# MU3E_HISTOGRAM_STATISTICS register map
Vendor: Mu3e; Series: MU3E_FPGA_IP; File version: 26.3.0.0515
CMSIS-SVD description of the histogram statistics CSR window. BaseAddress is 0 because this file describes the relative CSR aperture of the IP; system integration supplies the live slave base address.
Registers are 32-bit, read-only, reset 0x0 unless marked. A register's access mark holds for its fields unless they carry their own. Offsets are from the block's base; lines under a group give offsets from that group; [hi:lo] are bit positions; {n}, {i} and the like mark numbered series; 'fields as' and 'values as' point back to an identical list; <NAME> marks a mode.

## Memory map
0x00000000 HISTOGRAM_STATISTICS_CSR size 0x4C — Relative 19-word CSR aperture for histogram statistics. The separate hist_bin data window is intentionally excluded because it is histogram memory, not control/status registers.

## HISTOGRAM_STATISTICS_CSR — Relative 19-word CSR aperture for histogram statistics. The separate hist_bin data window is intentionally excluded because it is histogram memory, not control/status registers.
Base 0x00000000
0x00 UID reset 0x48495354 — Software-visible IP identifier. Default ASCII "HIST" (0x48495354).
  [31:0] value — Compile-time or integration-time UID word. Default ASCII "HIST".
0x04 META rw — Read-multiplexed metadata word. Write meta_sel[1:0] before reading back: 0=VERSION, 1=DATE, 2=GIT, 3=INSTANCE_ID.
  [1:0] meta_sel — Selects the META read page.
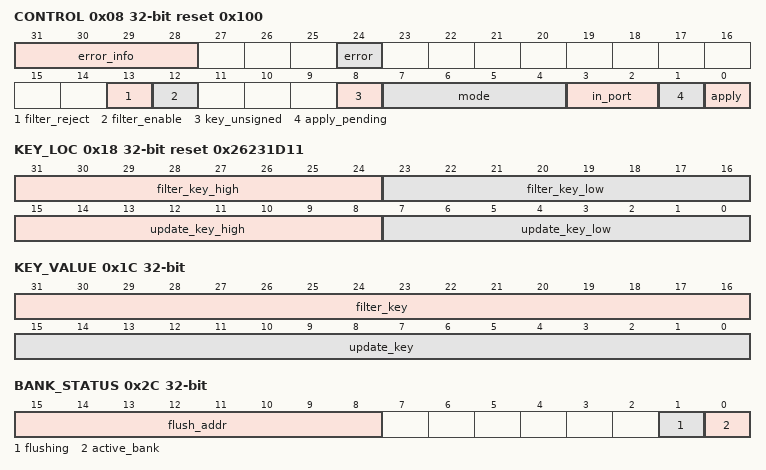
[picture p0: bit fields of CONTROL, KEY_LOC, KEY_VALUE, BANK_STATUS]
0x08 CONTROL rw reset 0x100 — Configuration apply, mode, key interpretation, filter control, and validation status.
  [31:28] error_info ro — Validation error code. 0x1 indicates invalid bounds in auto-right-bound mode; 0x2 indicates invalid in_port.
  [24] error ro — Set when the last apply request failed CSR validation.
  [13] filter_reject — 0 accepts matching events, 1 rejects matching events.
  [12] filter_enable — Enables the runtime filter-key comparison.
  [8] key_unsigned — 1 selects unsigned update-key interpretation, 0 selects signed extraction.
  [7:4] mode — Mode selector. Mode 0 bins the selected stream key directly. Mode 1 bins stream delay: for in_port 1 or 2, data[86:39] from the selected extended source is the true hit timestamp; for in_port 0, the selected update-key slice is used as before. Negative signed values -1..-6 route debug_1..debug_6 individually; -7 samples signed MTS-delay streams on debug_1 and debug_2 together. In debug modes the CSR filter compares a synthetic debug word: bits [15:0] sample, [23:16] zero-based debug source, [31:24] absolute debug mode.
  [3:2] in_port — Histogram ingress source. 0 selects the normal fill-in merge, 1 selects hit_type1_extended_0, and 2 selects hit_type1_extended_1. Value 3 is rejected on apply.
  [1] apply_pending ro — 1 while a committed configuration is waiting to settle into the live datapath.
  [0] apply — Write 1 to request that the staged configuration becomes active after the ingress path drains.
0x0C LEFT_BOUND rw — Signed left boundary of the histogram range.
  [31:0] value — Signed left boundary.
0x10 RIGHT_BOUND rw — Signed right boundary of the histogram range. Recomputed at apply time when BIN_WIDTH != 0.
  [31:0] value — Signed right boundary.
0x14 BIN_WIDTH rw — Bin width in key-space units. Set to 0 to keep explicit left and right bounds.
  [15:0] value — Bin width in key-space units.
0x18 KEY_LOC rw reset 0x26231D11 — Packed bit-slice locations for update-key and filter-key extraction.
  [31:24] filter_key_high — MSB of the filter-key slice inside the snooped data word. In debug modes this selects the synthetic debug word.
  [23:16] filter_key_low — LSB of the filter-key slice inside the snooped data word. In debug modes this selects the synthetic debug word.
  [15:8] update_key_high — MSB of the update-key slice inside the snooped data word.
  [7:0] update_key_low — LSB of the update-key slice inside the snooped data word.
0x1C KEY_VALUE rw — Packed runtime key overrides used by mode-dependent histogram logic.
  [31:16] filter_key — Literal filter-key comparison value.
  [15:0] update_key — Literal update-key override.
0x20 UNDERFLOW_COUNT — Count of keys mapped below the configured range.
  [31:0] value — Underflow event count.
0x24 OVERFLOW_COUNT — Count of keys mapped above the configured range.
  [31:0] value — Overflow event count.
0x28 INTERVAL_CFG rw — Ping-pong interval timer configuration in clock cycles.
  [31:0] value — Interval length in clock cycles.
0x2C BANK_STATUS — Ping-pong bank-selection and flush-progress status.
  [15:8] flush_addr — Bin index currently being cleared.
  [1] flushing — 1 while the next active bank is being cleared.
  [0] active_bank — Currently active write bank.
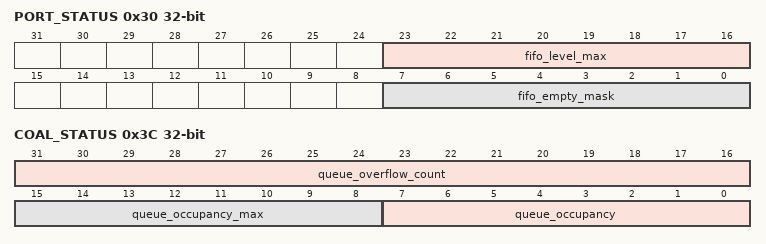
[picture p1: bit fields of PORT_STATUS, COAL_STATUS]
0x30 PORT_STATUS — Ingress FIFO empty-mask and maximum observed fill level.
  [23:16] fifo_level_max — Maximum observed FIFO fill level across the ingress-port pairs.
  [7:0] fifo_empty_mask — One bit per ingress FIFO. 1 indicates the corresponding FIFO is empty.
0x34 TOTAL_HITS — Live accepted-hit count in the current interval. Resets at manual clear and at every interval pulse.
  [31:0] value — Current-interval accepted-hit count.
0x38 DROPPED_HITS — Live dropped-hit count caused by FIFO or queue overflow in the current interval. Resets at manual clear and at every interval pulse.
  [31:0] value — Current-interval dropped-hit count.
0x3C COAL_STATUS — Coalescing-queue occupancy, occupancy maximum, and overflow count.
  [31:16] queue_overflow_count — Total number of queue-overflow events.
  [15:8] queue_occupancy_max — Maximum queue occupancy observed in the current interval.
  [7:0] queue_occupancy — Current coalescing-queue occupancy.
0x40 SCRATCH rw — General-purpose scratch register for integration testing.
  [31:0] value — Scratch value.
0x44 LAST_INTERVAL_TOTAL_HITS — Accepted-hit count latched at the most recent interval pulse before the live counter reset.
  [31:0] value — Last completed interval accepted-hit count.
0x48 LAST_INTERVAL_DROPPED_HITS — Dropped-hit count latched at the most recent interval pulse before the live counter reset.
  [31:0] value — Last completed interval dropped-hit count.
